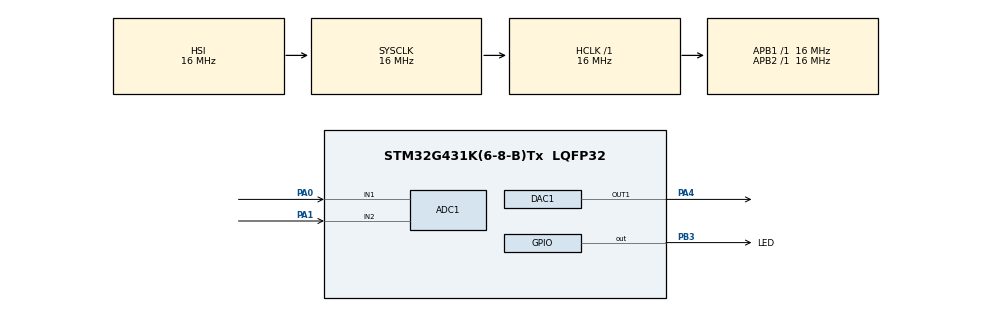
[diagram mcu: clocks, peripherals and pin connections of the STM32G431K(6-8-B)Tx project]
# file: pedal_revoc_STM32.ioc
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ADC1.Channel-0\#ChannelRegularConversion=ADC_CHANNEL_1
ADC1.NbrOfConversionFlag=1
ADC1.OffsetNumber-0\#ChannelRegularConversion=ADC_OFFSET_NONE
ADC1.Rank-0\#ChannelRegularConversion=1
ADC1.SamplingTime-0\#ChannelRegularConversion=ADC_SAMPLETIME_2CYCLES_5
ADC1.SingleDiff-0\#ChannelRegularConversion=ADC_DIFFERENTIAL_ENDED
ADC1.master=1
Mcu.Family=STM32G4
Mcu.Name=STM32G431K(6-8-B)Tx
Mcu.Package=LQFP32
NVIC.PriorityGroup=NVIC_PRIORITYGROUP_4
PA0.Mode=IN1-Differential
PA0.Signal=ADC1_IN1
PA1.Mode=IN1-Differential
PA1.Signal=ADC1_IN2
PA4.Signal=COMP_DAC11_group
PB3.GPIO_Label=LED
PB3.Signal=GPIO_Output
ProjectManager.HeapSize=0x200
ProjectManager.StackSize=0x400
ProjectManager.TargetToolchain=STM32CubeIDE
RCC.AHBFreq_Value=16000000
RCC.APB1Freq_Value=16000000
RCC.APB1TimFreq_Value=16000000
RCC.APB2Freq_Value=16000000
RCC.APB2TimFreq_Value=16000000
RCC.CortexFreq_Value=16000000
RCC.EXTERNAL_CLOCK_VALUE=12288000
RCC.HCLKFreq_Value=16000000
RCC.HSE_VALUE=8000000
RCC.HSI48_VALUE=48000000
RCC.HSI_VALUE=16000000
RCC.LSE_VALUE=32768
RCC.SYSCLKFreq_VALUE=16000000
RCC.USBFreq_Value=64000000
RCC.VCOOutputFreq_Value=128000000
SH.COMP_DAC11_group.0=DAC1_OUT1,DAC_OUT1
board=custom

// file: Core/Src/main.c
/* USER CODE BEGIN Header */
/**
  ******************************************************************************
  * @file           : main.c
  * @brief          : Main program body
  ******************************************************************************
  * @attention
  *
  * Copyright (c) 2023 STMicroelectronics.
  * All rights reserved.
  *
  * This software is licensed under terms that can be found in the LICENSE file
  * in the root directory of this software component.
  * If no LICENSE file comes with this software, it is provided AS-IS.
  *
  ******************************************************************************
  */
/* USER CODE END Header */
#include "main.h"
#include "adc.h"
#include "dac.h"
#include "gpio.h"

/* USER CODE BEGIN PV */
uint32_t DAC_buff[4] = {0, 1241, 2482, 3723};
/* USER CODE END PV */

void SystemClock_Config(void);

int main(void)
{

  /* MCU Configuration--------------------------------------------------------*/

  /* Reset of all peripherals, Initializes the Flash interface and the Systick. */
  HAL_Init();

  /* Configure the system clock */
  SystemClock_Config();

  /* Initialize all configured peripherals */
  MX_GPIO_Init();
  MX_ADC1_Init();
  MX_DAC1_Init();
  /* USER CODE BEGIN 2 */
  HAL_GPIO_WritePin(LED_GPIO_Port, LED_Pin, GPIO_PIN_SET);
  HAL_GPIO_WritePin(LED_GPIO_Port, LED_Pin, GPIO_PIN_RESET);
  HAL_DAC_Start(&hdac1, DAC_CHANNEL_1);

  /* USER CODE END 2 */

  /* Infinite loop */
  /* USER CODE BEGIN WHILE */
  while (1)
  {
//	  DAC1->DHR12R1 = DAC_OUT[i++];
	  HAL_DAC_SetValue(&hdac1, DAC_CHANNEL_1, DAC_ALIGN_12B_R, DAC_OUT[i++]);
	  if(i == 4)
	  {
		  i = 0;
	  }
	  HAL_Delay(50); //Min DAC delay
    /* USER CODE END WHILE */

  }
}

void SystemClock_Config(void)
{
  RCC_OscInitTypeDef RCC_OscInitStruct = {0};
  RCC_ClkInitTypeDef RCC_ClkInitStruct = {0};

  /** Configure the main internal regulator output voltage
  */
  HAL_PWREx_ControlVoltageScaling(PWR_REGULATOR_VOLTAGE_SCALE1);

  /** Initializes the RCC Oscillators according to the specified parameters
  * in the RCC_OscInitTypeDef structure.
  */
  RCC_OscInitStruct.OscillatorType = RCC_OSCILLATORTYPE_HSI;
  RCC_OscInitStruct.HSIState = RCC_HSI_ON;
  RCC_OscInitStruct.HSICalibrationValue = RCC_HSICALIBRATION_DEFAULT;
  RCC_OscInitStruct.PLL.PLLState = RCC_PLL_NONE;
  if (HAL_RCC_OscConfig(&RCC_OscInitStruct) != HAL_OK)
  {
    Error_Handler();
  }

  /** Initializes the CPU, AHB and APB buses clocks
  */
  RCC_ClkInitStruct.ClockType = RCC_CLOCKTYPE_HCLK|RCC_CLOCKTYPE_SYSCLK
                              |RCC_CLOCKTYPE_PCLK1|RCC_CLOCKTYPE_PCLK2;
  RCC_ClkInitStruct.SYSCLKSource = RCC_SYSCLKSOURCE_HSI;
  RCC_ClkInitStruct.AHBCLKDivider = RCC_SYSCLK_DIV1;
  RCC_ClkInitStruct.APB1CLKDivider = RCC_HCLK_DIV1;
  RCC_ClkInitStruct.APB2CLKDivider = RCC_HCLK_DIV1;

  if (HAL_RCC_ClockConfig(&RCC_ClkInitStruct, FLASH_LATENCY_0) != HAL_OK)
  {
    Error_Handler();
  }
}

void Error_Handler(void)
{
  __disable_irq();
  while (1)
  {
  }
}
